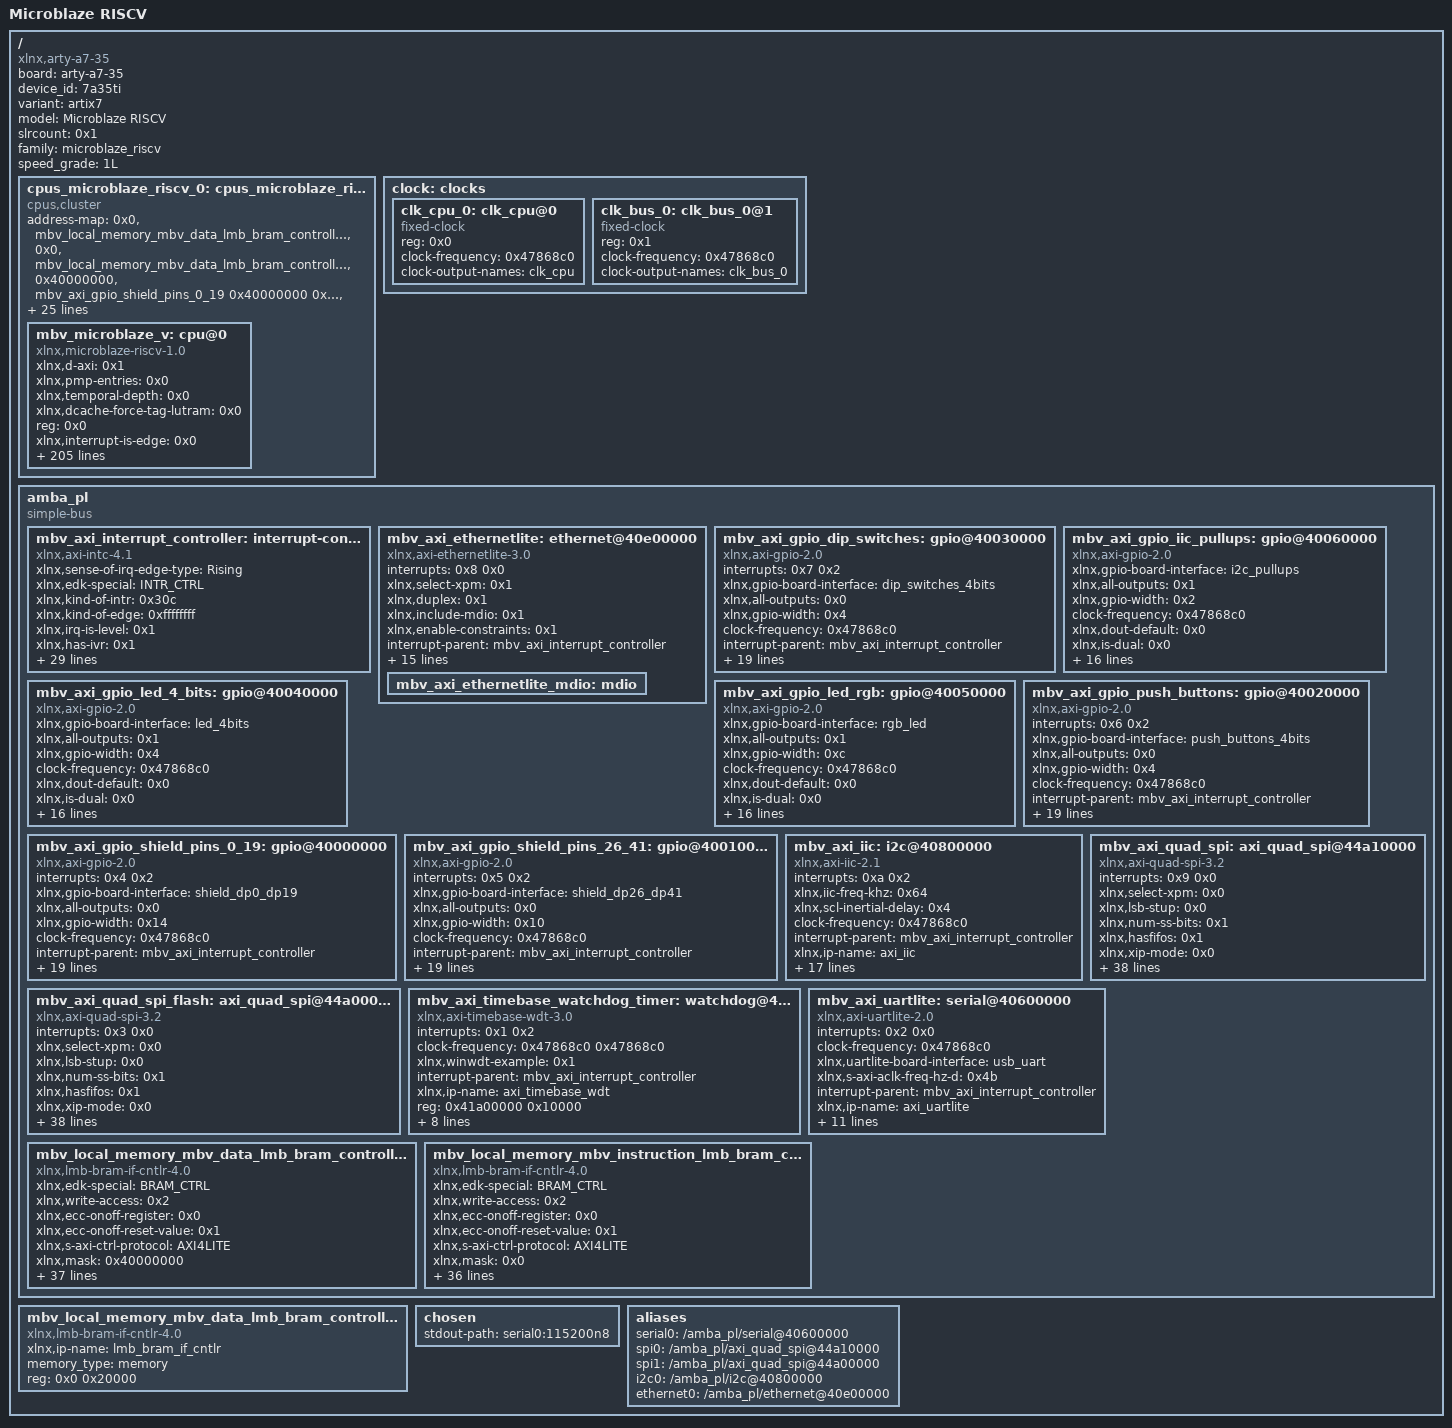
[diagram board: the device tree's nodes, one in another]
/dts-v1/;
/ {
        board = "arty-a7-35";
        compatible = "xlnx,arty-a7-35";
        device_id = "7a35ti";
        #address-cells = <0x1>;
        variant = "artix7";
        model = "Microblaze RISCV";
        #size-cells = <0x1>;
        slrcount = <0x1>;
        family = "microblaze_riscv";
        speed_grade = "1L";

        cpus_microblaze_riscv_0: cpus_microblaze_riscv@0 {
                phandle = <0x13>;
                #cpu-mask-cells = <0x1>;
                compatible = "cpus,cluster";
                #address-cells = <0x1>;
                #size-cells = <0x0>;
                address-map = <0x0 &mbv_local_memory_mbv_data_lmb_bram_controller_memory 0x0 0x20000>,
                 <0x0 &mbv_local_memory_mbv_data_lmb_bram_controller 0x0 0x20000>,
                 <0x40000000 &mbv_axi_gpio_shield_pins_0_19 0x40000000 0x10000>,
                 <0x40010000 &mbv_axi_gpio_shield_pins_26_41 0x40010000 0x10000>,
                 <0x40020000 &mbv_axi_gpio_push_buttons 0x40020000 0x10000>,
                 <0x40030000 &mbv_axi_gpio_dip_switches 0x40030000 0x10000>,
                 <0x40040000 &mbv_axi_gpio_led_4_bits 0x40040000 0x10000>,
                 <0x40050000 &mbv_axi_gpio_led_rgb 0x40050000 0x10000>,
                 <0x40060000 &mbv_axi_gpio_iic_pullups 0x40060000 0x10000>,
                 <0x40600000 &mbv_axi_uartlite 0x40600000 0x10000>,
                 <0x40800000 &mbv_axi_iic 0x40800000 0x10000>,
                 <0x40e00000 &mbv_axi_ethernetlite 0x40e00000 0x10000>,
                 <0x41200000 &mbv_axi_interrupt_controller 0x41200000 0x10000>,
                 <0x41a00000 &mbv_axi_timebase_watchdog_timer 0x41a00000 0x10000>,
                 <0x44a00000 &mbv_axi_quad_spi_flash 0x44a00000 0x10000>,
                 <0x44a10000 &mbv_axi_quad_spi 0x44a10000 0x10000>;
                #ranges-address-cells = <0x1>;
                #ranges-size-cells = <0x1>;

                mbv_microblaze_v: cpu@0 {
                        phandle = <0x14>;
                        xlnx,d-axi = <0x1>;
                        xlnx,pmp-entries = <0x0>;
                        xlnx,temporal-depth = <0x0>;
                        xlnx,dcache-force-tag-lutram = <0x0>;
                        reg = <0x0>;
                        xlnx,interrupt-is-edge = <0x0>;
                        xlnx,use-mmu = <0x3>;
                        xlnx,dc-axi-mon = <0x0>;
                        xlnx,debug-trace-async-reset = <0x0>;
                        xlnx,part = "xc7a35ticsg324-1l";
                        xlnx,use-config-reset = <0x0>;
                        xlnx,family = "artix7";
                        xlnx,use-sleep = <0x0>;
                        xlnx,d-lmb = <0x1>;
                        xlnx,enable-discrete-ports = <0x0>;
                        xlnx,debug-interface = <0x0>;
                        xlnx,use-ext-brk = <0x0>;
                        xlnx,debug-enabled = <0x1>;
                        xlnx,daddr-size = <0x20>;
                        xlnx,use-extended-fsl-instr = <0x0>;
                        xlnx,branch-target-cache-size = <0x0>;
                        bus-handle = <&amba_pl>;
                        xlnx,pmp-addr0 = <0x0>;
                        xlnx,pmp-addr1 = <0x0>;
                        xlnx,pmp-addr2 = <0x0>;
                        xlnx,pmp-addr3 = <0x0>;
                        xlnx,pmp-addr4 = <0x0>;
                        xlnx,edk-special = "microblaze_riscv";
                        xlnx,use-dcache = <0x0>;
                        xlnx,pmp-addr5 = <0x0>;
                        xlnx,use-muldiv = <0x2>;
                        xlnx,pmp-addr6 = <0x0>;
                        xlnx,use-axi-dp-ext-addr = <0x0>;
                        xlnx,pmp-addr7 = <0x0>;
                        xlnx,pmp-addr8 = <0x0>;
                        xlnx,pmp-addr9 = <0x0>;
                        xlnx,i-axi = <0x0>;
                        xlnx,icache-streams = <0x0>;
                        xlnx,i-lmb-has-prot = <0x0>;
                        xlnx,num-sync-ff-dbg-clk = <0x1>;
                        xlnx,icache-byte-size = <0x2000>;
                        xlnx,pmp-addr10 = <0x0>;
                        d-cache-size = <0x2000>;
                        xlnx,pmp-addr11 = <0x0>;
                        xlnx,pmp-addr12 = <0x0>;
                        xlnx,pmp-addr13 = <0x0>;
                        xlnx,pmp-addr14 = <0x0>;
                        xlnx,pmp-addr15 = <0x0>;
                        xlnx,avoid-primitives = <0x0>;
                        xlnx,pmp-addr16 = <0x0>;
                        xlnx,pmp-addr17 = <0x0>;
                        xlnx,pmp-addr18 = <0x0>;
                        xlnx,pdaddr-size = <0x22>;
                        xlnx,pmp-addr19 = <0x0>;
                        xlnx,pmp-addr20 = <0x0>;
                        xlnx,pmp-addr21 = <0x0>;
                        xlnx,i-lmb = <0x1>;
                        xlnx,pmp-addr22 = <0x0>;
                        xlnx,lmb-data-size = <0x20>;
                        xlnx,lockstep-select = <0x0>;
                        xlnx,pmp-addr23 = <0x0>;
                        timebase-frequency = <0x47868c0>;
                        xlnx,pmp-addr24 = <0x0>;
                        xlnx,dcache-data-width = <0x0>;
                        xlnx,icache-force-tag-lutram = <0x0>;
                        xlnx,pmp-addr25 = <0x0>;
                        xlnx,pmp-addr26 = <0x0>;
                        xlnx,use-branch-target-cache = <0x0>;
                        xlnx,pmp-addr27 = <0x0>;
                        xlnx,number-of-pc-brk = <0x8>;
                        xlnx,pmp-addr28 = <0x0>;
                        xlnx,imprecise-exceptions = <0x0>;
                        xlnx,pmp-addr29 = <0x0>;
                        xlnx,pmp-addr30 = <0x0>;
                        xlnx,pmp-addr31 = <0x0>;
                        xlnx,pmp-addr32 = <0x0>;
                        model = "microblaze_riscv,1.0";
                        xlnx,pmp-addr33 = <0x0>;
                        xlnx,pmp-addr34 = <0x0>;
                        xlnx,pmp-addr35 = <0x0>;
                        xlnx,pmp-addr36 = <0x0>;
                        d-cache-highaddr = <0x3fffffff>;
                        xlnx,optimization = <0x0>;
                        xlnx,pmp-addr37 = <0x0>;
                        xlnx,pmp-addr38 = <0x0>;
                        xlnx,pmp-addr39 = <0x0>;
                        xlnx,pmp-addr40 = <0x0>;
                        xlnx,pmp-addr41 = <0x0>;
                        xlnx,d-lmb-mon = <0x0>;
                        xlnx,pmp-addr42 = <0x0>;
                        xlnx,pmp-addr43 = <0x0>;
                        xlnx,pmp-addr44 = <0x0>;
                        xlnx,pmp-addr45 = <0x0>;
                        xlnx,pmp-addr46 = <0x0>;
                        xlnx,pmp-addr47 = <0x0>;
                        xlnx,pmp-addr48 = <0x0>;
                        xlnx,fault-tolerant = <0x0>;
                        xlnx,pmp-addr49 = <0x0>;
                        xlnx,pmp-addr50 = <0x0>;
                        xlnx,pmp-addr51 = <0x0>;
                        xlnx,pmp-enhancements = <0x0>;
                        d-cache-line-size = <0x10>;
                        xlnx,mmu-privileged-instr = <0x0>;
                        xlnx,pmp-addr52 = <0x0>;
                        clock-frequency = <0x47868c0>;
                        xlnx,pmp-addr53 = <0x0>;
                        xlnx,pmp-addr54 = <0x0>;
                        xlnx,pmp-addr55 = <0x0>;
                        xlnx,i-lmb-protocol = <0x0>;
                        xlnx,pmp-addr56 = <0x0>;
                        xlnx,pmp-addr57 = <0x0>;
                        xlnx,dp-axi-mon = <0x0>;
                        xlnx,pmp-addr58 = <0x0>;
                        xlnx,pmp-addr59 = <0x0>;
                        xlnx,pmp-addr60 = <0x0>;
                        xlnx,pmp-addr61 = <0x0>;
                        xlnx,pmp-addr62 = <0x0>;
                        xlnx,pmp-addr63 = <0x0>;
                        xlnx,debug-external-trace = <0x1>;
                        xlnx,addr-size = <0x20>;
                        xlnx,debug-num-progbuf = <0x2>;
                        xlnx,debug-event-counters = <0xd>;
                        xlnx,edk-iptype = "PROCESSOR";
                        xlnx,debug-latency-counters = <0x8>;
                        xlnx,interconnect = <0x2>;
                        xlnx,edge-is-positive = <0x1>;
                        xlnx,use-icache = <0x0>;
                        xlnx,async-wakeup = <0x3>;
                        xlnx,s-axi = <0x0>;
                        xlnx,use-ext-nm-brk = <0x0>;
                        xlnx,ic-axi-mon = <0x0>;
                        xlnx,archid = <0x1>;
                        xlnx,num-sync-ff-clk-irq = <0x1>;
                        xlnx,freq = <0x47868c0>;
                        xlnx,lockstep-master = <0x0>;
                        xlnx,pmp-cfg0 = <0x0>;
                        xlnx,pmp-cfg1 = <0x0>;
                        xlnx,iaddr-size = <0x20>;
                        xlnx,interrupt-mon = <0x0>;
                        xlnx,pmp-cfg2 = <0x0>;
                        xlnx,number-of-wr-addr-brk = <0x4>;
                        xlnx,pmp-cfg3 = <0x0>;
                        xlnx,pmp-cfg4 = <0x0>;
                        xlnx,use-interrupt = <0x2>;
                        xlnx,pmp-cfg5 = <0x0>;
                        xlnx,async-interrupt = <0x1>;
                        xlnx,pc-width = <0x11>;
                        xlnx,pmp-cfg6 = <0x0>;
                        xlnx,icache-victims = <0x0>;
                        xlnx,pmp-cfg7 = <0x0>;
                        xlnx,pmp-cfg8 = <0x0>;
                        xlnx,pmp-cfg9 = <0x0>;
                        xlnx,use-bitman-a = <0x1>;
                        xlnx,use-bitman-b = <0x1>;
                        xlnx,use-bitman-c = <0x1>;
                        xlnx,i-lmb-mon = <0x0>;
                        xlnx,dcache-byte-size = <0x2000>;
                        xlnx,data-size = <0x20>;
                        compatible = "xlnx,microblaze-riscv-1.0", "xlnx,microblaze_riscv";
                        xlnx,pmp-debug-inhibit = <0x0>;
                        xlnx,use-sstc = <0x1>;
                        xlnx,fsl-exception = <0x0>;
                        xlnx,dcache-use-writeback = <0x0>;
                        device_type = "cpu";
                        xlnx,impid = <0x1>;
                        xlnx,use-bitman-s = <0x1>;
                        xlnx,base-vectors = <0x0>;
                        xlnx,icache-line-len = <0x4>;
                        xlnx,d-lmb-has-prot = <0x0>;
                        xlnx,use-barrel = <0x1>;
                        xlnx,misaligned-exceptions = <0x1>;
                        xlnx,piaddr-size = <0x22>;
                        xlnx,use-bitman = <0xf>;
                        xlnx,dcache-line-len = <0x4>;
                        xlnx,num-sync-ff-clk = <0x2>;
                        xlnx,memory-ip-list = "mbv_local_memory_mbv_instruction_lmb_bram_controller_memory", "mbv_local_memory_mbv_data_lmb_bram_controller_memory";
                        xlnx,number-of-rd-addr-brk = <0x4>;
                        xlnx,use-counters = <0x1>;
                        xlnx,lockstep-slave = <0x0>;
                        interrupt-handle = <&mbv_axi_interrupt_controller>;
                        xlnx,pmp-cfg10 = <0x0>;
                        xlnx,pmp-cfg11 = <0x0>;
                        xlnx,debug-profile-size = <0x0>;
                        xlnx,pmp-cfg12 = <0x0>;
                        xlnx,pmp-cfg13 = <0x0>;
                        xlnx,pmp-cfg14 = <0x0>;
                        xlnx,pmp-cfg15 = <0x0>;
                        xlnx,debug-counter-width = <0x40>;
                        xlnx,icache-data-width = <0x0>;
                        xlnx,ip-name = "microblaze_riscv";
                        xlnx,ip-axi-mon = <0x0>;
                        xlnx,d-lmb-protocol = <0x0>;
                        xlnx,trace = <0x0>;
                        xlnx,ill-instr-exception = <0x2>;
                        xlnx,debug-trace-size = <0x0>;
                        xlnx,pmp-granularity = <0x2>;
                        xlnx,num-sync-ff-dbg-trace-clk = <0x2>;
                        xlnx,ecc-use-ce-exception = <0x0>;
                        xlnx,num-sync-ff-clk-debug = <0x2>;
                        xlnx,use-atomic = <0x1>;
                        xlnx,g-template-list = <0x0>;
                        xlnx,trap-enhancement = <0x0>;
                        xlnx,hartid = <0x0>;
                        xlnx,use-fpu = <0x0>;
                        xlnx,use-non-secure = <0x0>;
                        d-cache-baseaddr = <0x0>;
                        xlnx,use-compression = <0x1>;
                        xlnx,instr-size = <0x20>;
                        xlnx,fsl-links = <0x0>;
                        xlnx,dcache-victims = <0x0>;
                        xlnx,pmp-read-only = <0x0>;
                };
        };

        clock: clocks {
                phandle = <0x15>;
                #address-cells = <0x1>;
                #size-cells = <0x0>;

                clk_cpu_0: clk_cpu@0 {
                        phandle = <0x16>;
                        compatible = "fixed-clock";
                        reg = <0x0>;
                        clock-frequency = <0x47868c0>;
                        clock-output-names = "clk_cpu";
                        #clock-cells = <0x0>;
                };

                clk_bus_0: clk_bus_0@1 {
                        phandle = <0x12>;
                        compatible = "fixed-clock";
                        reg = <0x1>;
                        clock-frequency = <0x47868c0>;
                        clock-output-names = "clk_bus_0";
                        #clock-cells = <0x0>;
                };
        };

        amba_pl: amba_pl {
                phandle = <0x11>;
                ranges;
                compatible = "simple-bus";
                #address-cells = <0x1>;
                #size-cells = <0x1>;

                mbv_axi_interrupt_controller: interrupt-controller@41200000 {
                        phandle = <0xd>;
                        #interrupt-cells = <0x2>;
                        xlnx,sense-of-irq-edge-type = "Rising";
                        xlnx,edk-special = "INTR_CTRL";
                        xlnx,kind-of-intr = <0x30c>;
                        xlnx,kind-of-edge = <0xffffffff>;
                        xlnx,irq-is-level = <0x1>;
                        xlnx,has-ivr = <0x1>;
                        compatible = "xlnx,axi-intc-4.1", "xlnx,xps-intc-1.00.a";
                        xlnx,disable-synchronizers = <0x1>;
                        xlnx,kind-of-lvl = <0xffffffff>;
                        xlnx,ivar-reset-value = <0x10>;
                        xlnx,irq-active = <0x1>;
                        xlnx,en-cascade-mode = <0x0>;
                        xlnx,ip-name = "axi_intc";
                        xlnx,has-ilr = <0x0>;
                        reg = <0x41200000 0x10000>;
                        xlnx,addr-width = <0x20>;
                        xlnx,s-axi-aclk-freq-mhz = <0x4b>;
                        xlnx,num-sw-intr = <0x0>;
                        xlnx,irq-connection = <0x0>;
                        xlnx,num-intr-inputs = <0xb>;
                        xlnx,has-sie = <0x1>;
                        xlnx,enable-async = <0x0>;
                        xlnx,has-cie = <0x1>;
                        xlnx,num-sync-ff = <0x2>;
                        xlnx,edk-iptype = "PERIPHERAL";
                        xlnx,mb-clk-not-connected = <0x1>;
                        xlnx,has-ipr = <0x1>;
                        xlnx,sense-of-irq-level-type = "Active_High";
                        xlnx,cascade-master = <0x0>;
                        xlnx,processor-clk-freq-mhz = <0x4b>;
                        status = "okay";
                        xlnx,is-fast = <0x1>;
                        xlnx,has-fast = <0x1>;
                        xlnx,ivar-rst-val = <0x10>;
                        interrupt-controller;
                        xlnx,async-intr = <0xfffff900>;
                        xlnx,name = "mbv_axi_interrupt_controller";
                };

                mbv_axi_ethernetlite: ethernet@40e00000 {
                        phandle = <0xc>;
                        interrupts = <0x8 0x0>;
                        xlnx,select-xpm = <0x1>;
                        compatible = "xlnx,axi-ethernetlite-3.0", "xlnx,axi-ethernetlite-3.0", "xlnx,xps-ethernetlite-1.00.a";
                        xlnx,duplex = <0x1>;
                        xlnx,include-mdio = <0x1>;
                        xlnx,enable-constraints = <0x1>;
                        interrupt-parent = <&mbv_axi_interrupt_controller>;
                        xlnx,rx-ping-pong = <0x1>;
                        xlnx,ip-name = "axi_ethernetlite";
                        xlnx,tx-ping-pong = <0x1>;
                        reg = <0x40e00000 0x10000>;
                        xlnx,mii-board-interface = "eth_mii";
                        xlnx,mdio-board-interface = "eth_mdio_mdc";
                        xlnx,edk-iptype = "PERIPHERAL";
                        xlnx,include-global-buffers = <0x1>;
                        local-mac-address = [00 0A 23 00 00 00];
                        status = "okay";
                        xlnx,include-internal-loopback = <0x0>;
                        xlnx,use-board-flow;
                        xlnx,use-internal = <0x0>;
                        interrupt-names = "ip2intc_irpt";
                        xlnx,name = "mbv_axi_ethernetlite";
                        xlnx,axi-aclk-freq-mhz = <0x4b>;
                        xlnx,s-axi-id-width = <0x1>;

                        mbv_axi_ethernetlite_mdio: mdio {
                                phandle = <0x17>;
                                #address-cells = <0x1>;
                                #size-cells = <0x0>;
                        };
                };

                mbv_axi_gpio_dip_switches: gpio@40030000 {
                        phandle = <0x6>;
                        #interrupt-cells = <0x2>;
                        interrupts = <0x7 0x2>;
                        xlnx,gpio-board-interface = "dip_switches_4bits";
                        compatible = "xlnx,axi-gpio-2.0", "xlnx,xps-gpio-1.00.a";
                        xlnx,all-outputs = <0x0>;
                        #gpio-cells = <0x2>;
                        xlnx,gpio-width = <0x4>;
                        clock-frequency = <0x47868c0>;
                        interrupt-parent = <&mbv_axi_interrupt_controller>;
                        xlnx,dout-default = <0x0>;
                        xlnx,is-dual = <0x0>;
                        xlnx,ip-name = "axi_gpio";
                        xlnx,tri-default-2 = <0xffffffff>;
                        reg = <0x40030000 0x10000>;
                        xlnx,all-inputs-2 = <0x0>;
                        clocks = <&clk_bus_0>;
                        xlnx,all-outputs-2 = <0x0>;
                        gpio-controller;
                        xlnx,interrupt-present = <0x1>;
                        xlnx,gpio2-board-interface = "Custom";
                        xlnx,edk-iptype = "PERIPHERAL";
                        xlnx,dout-default-2 = <0x0>;
                        status = "okay";
                        xlnx,gpio2-width = <0x20>;
                        clock-names = "s_axi_aclk";
                        xlnx,use-board-flow;
                        interrupt-controller;
                        interrupt-names = "ip2intc_irpt";
                        xlnx,tri-default = <0xffffffff>;
                        xlnx,name = "mbv_axi_gpio_dip_switches";
                        xlnx,all-inputs = <0x1>;
                };

                mbv_axi_gpio_iic_pullups: gpio@40060000 {
                        phandle = <0x9>;
                        xlnx,gpio-board-interface = "i2c_pullups";
                        compatible = "xlnx,axi-gpio-2.0", "xlnx,xps-gpio-1.00.a";
                        xlnx,all-outputs = <0x1>;
                        #gpio-cells = <0x2>;
                        xlnx,gpio-width = <0x2>;
                        clock-frequency = <0x47868c0>;
                        xlnx,dout-default = <0x0>;
                        xlnx,is-dual = <0x0>;
                        xlnx,ip-name = "axi_gpio";
                        xlnx,tri-default-2 = <0xffffffff>;
                        reg = <0x40060000 0x10000>;
                        xlnx,all-inputs-2 = <0x0>;
                        clocks = <&clk_bus_0>;
                        xlnx,all-outputs-2 = <0x0>;
                        gpio-controller;
                        xlnx,interrupt-present = <0x0>;
                        xlnx,gpio2-board-interface = "Custom";
                        xlnx,edk-iptype = "PERIPHERAL";
                        xlnx,dout-default-2 = <0x0>;
                        status = "okay";
                        xlnx,gpio2-width = <0x20>;
                        clock-names = "s_axi_aclk";
                        xlnx,use-board-flow;
                        xlnx,tri-default = <0xffffffff>;
                        xlnx,name = "mbv_axi_gpio_iic_pullups";
                        xlnx,all-inputs = <0x0>;
                };

                mbv_axi_gpio_led_4_bits: gpio@40040000 {
                        phandle = <0x7>;
                        xlnx,gpio-board-interface = "led_4bits";
                        compatible = "xlnx,axi-gpio-2.0", "xlnx,xps-gpio-1.00.a";
                        xlnx,all-outputs = <0x1>;
                        #gpio-cells = <0x2>;
                        xlnx,gpio-width = <0x4>;
                        clock-frequency = <0x47868c0>;
                        xlnx,dout-default = <0x0>;
                        xlnx,is-dual = <0x0>;
                        xlnx,ip-name = "axi_gpio";
                        xlnx,tri-default-2 = <0xffffffff>;
                        reg = <0x40040000 0x10000>;
                        xlnx,all-inputs-2 = <0x0>;
                        clocks = <&clk_bus_0>;
                        xlnx,all-outputs-2 = <0x0>;
                        gpio-controller;
                        xlnx,interrupt-present = <0x0>;
                        xlnx,gpio2-board-interface = "Custom";
                        xlnx,edk-iptype = "PERIPHERAL";
                        xlnx,dout-default-2 = <0x0>;
                        status = "okay";
                        xlnx,gpio2-width = <0x20>;
                        clock-names = "s_axi_aclk";
                        xlnx,use-board-flow;
                        xlnx,tri-default = <0xffffffff>;
                        xlnx,name = "mbv_axi_gpio_led_4_bits";
                        xlnx,all-inputs = <0x0>;
                };

                mbv_axi_gpio_led_rgb: gpio@40050000 {
                        phandle = <0x8>;
                        xlnx,gpio-board-interface = "rgb_led";
                        compatible = "xlnx,axi-gpio-2.0", "xlnx,xps-gpio-1.00.a";
                        xlnx,all-outputs = <0x1>;
                        #gpio-cells = <0x2>;
                        xlnx,gpio-width = <0xc>;
                        clock-frequency = <0x47868c0>;
                        xlnx,dout-default = <0x0>;
                        xlnx,is-dual = <0x0>;
                        xlnx,ip-name = "axi_gpio";
                        xlnx,tri-default-2 = <0xffffffff>;
                        reg = <0x40050000 0x10000>;
                        xlnx,all-inputs-2 = <0x0>;
                        clocks = <&clk_bus_0>;
                        xlnx,all-outputs-2 = <0x0>;
                        gpio-controller;
                        xlnx,interrupt-present = <0x0>;
                        xlnx,gpio2-board-interface = "Custom";
                        xlnx,edk-iptype = "PERIPHERAL";
                        xlnx,dout-default-2 = <0x0>;
                        status = "okay";
                        xlnx,gpio2-width = <0x20>;
                        clock-names = "s_axi_aclk";
                        xlnx,use-board-flow;
                        xlnx,tri-default = <0xffffffff>;
                        xlnx,name = "mbv_axi_gpio_led_rgb";
                        xlnx,all-inputs = <0x0>;
                };

                mbv_axi_gpio_push_buttons: gpio@40020000 {
                        phandle = <0x5>;
                        #interrupt-cells = <0x2>;
                        interrupts = <0x6 0x2>;
                        xlnx,gpio-board-interface = "push_buttons_4bits";
                        compatible = "xlnx,axi-gpio-2.0", "xlnx,xps-gpio-1.00.a";
                        xlnx,all-outputs = <0x0>;
                        #gpio-cells = <0x2>;
                        xlnx,gpio-width = <0x4>;
                        clock-frequency = <0x47868c0>;
                        interrupt-parent = <&mbv_axi_interrupt_controller>;
                        xlnx,dout-default = <0x0>;
                        xlnx,is-dual = <0x0>;
                        xlnx,ip-name = "axi_gpio";
                        xlnx,tri-default-2 = <0xffffffff>;
                        reg = <0x40020000 0x10000>;
                        xlnx,all-inputs-2 = <0x0>;
                        clocks = <&clk_bus_0>;
                        xlnx,all-outputs-2 = <0x0>;
                        gpio-controller;
                        xlnx,interrupt-present = <0x1>;
                        xlnx,gpio2-board-interface = "Custom";
                        xlnx,edk-iptype = "PERIPHERAL";
                        xlnx,dout-default-2 = <0x0>;
                        status = "okay";
                        xlnx,gpio2-width = <0x20>;
                        clock-names = "s_axi_aclk";
                        xlnx,use-board-flow;
                        interrupt-controller;
                        interrupt-names = "ip2intc_irpt";
                        xlnx,tri-default = <0xffffffff>;
                        xlnx,name = "mbv_axi_gpio_push_buttons";
                        xlnx,all-inputs = <0x1>;
                };

                mbv_axi_gpio_shield_pins_0_19: gpio@40000000 {
                        phandle = <0x3>;
                        #interrupt-cells = <0x2>;
                        interrupts = <0x4 0x2>;
                        xlnx,gpio-board-interface = "shield_dp0_dp19";
                        compatible = "xlnx,axi-gpio-2.0", "xlnx,xps-gpio-1.00.a";
                        xlnx,all-outputs = <0x0>;
                        #gpio-cells = <0x2>;
                        xlnx,gpio-width = <0x14>;
                        clock-frequency = <0x47868c0>;
                        interrupt-parent = <&mbv_axi_interrupt_controller>;
                        xlnx,dout-default = <0x0>;
                        xlnx,is-dual = <0x0>;
                        xlnx,ip-name = "axi_gpio";
                        xlnx,tri-default-2 = <0xffffffff>;
                        reg = <0x40000000 0x10000>;
                        xlnx,all-inputs-2 = <0x0>;
                        clocks = <&clk_bus_0>;
                        xlnx,all-outputs-2 = <0x0>;
                        gpio-controller;
                        xlnx,interrupt-present = <0x1>;
                        xlnx,gpio2-board-interface = "Custom";
                        xlnx,edk-iptype = "PERIPHERAL";
                        xlnx,dout-default-2 = <0x0>;
                        status = "okay";
                        xlnx,gpio2-width = <0x20>;
                        clock-names = "s_axi_aclk";
                        xlnx,use-board-flow;
                        interrupt-controller;
                        interrupt-names = "ip2intc_irpt";
                        xlnx,tri-default = <0xffffffff>;
                        xlnx,name = "mbv_axi_gpio_shield_pins_0_19";
                        xlnx,all-inputs = <0x0>;
                };

                mbv_axi_gpio_shield_pins_26_41: gpio@40010000 {
                        phandle = <0x4>;
                        #interrupt-cells = <0x2>;
                        interrupts = <0x5 0x2>;
                        xlnx,gpio-board-interface = "shield_dp26_dp41";
                        compatible = "xlnx,axi-gpio-2.0", "xlnx,xps-gpio-1.00.a";
                        xlnx,all-outputs = <0x0>;
                        #gpio-cells = <0x2>;
                        xlnx,gpio-width = <0x10>;
                        clock-frequency = <0x47868c0>;
                        interrupt-parent = <&mbv_axi_interrupt_controller>;
                        xlnx,dout-default = <0x0>;
                        xlnx,is-dual = <0x0>;
                        xlnx,ip-name = "axi_gpio";
                        xlnx,tri-default-2 = <0xffffffff>;
                        reg = <0x40010000 0x10000>;
                        xlnx,all-inputs-2 = <0x0>;
                        clocks = <&clk_bus_0>;
                        xlnx,all-outputs-2 = <0x0>;
                        gpio-controller;
                        xlnx,interrupt-present = <0x1>;
                        xlnx,gpio2-board-interface = "Custom";
                        xlnx,edk-iptype = "PERIPHERAL";
                        xlnx,dout-default-2 = <0x0>;
                        status = "okay";
                        xlnx,gpio2-width = <0x20>;
                        clock-names = "s_axi_aclk";
                        xlnx,use-board-flow;
                        interrupt-controller;
                        interrupt-names = "ip2intc_irpt";
                        xlnx,tri-default = <0xffffffff>;
                        xlnx,name = "mbv_axi_gpio_shield_pins_26_41";
                        xlnx,all-inputs = <0x0>;
                };

                mbv_axi_iic: i2c@40800000 {
                        phandle = <0xb>;
                        interrupts = <0xa 0x2>;
                        xlnx,iic-freq-khz = <0x64>;
                        compatible = "xlnx,axi-iic-2.1", "xlnx,xps-iic-2.00.a";
                        xlnx,scl-inertial-delay = <0x4>;
                        clock-frequency = <0x47868c0>;
                        interrupt-parent = <&mbv_axi_interrupt_controller>;
                        xlnx,ip-name = "axi_iic";
                        xlnx,disable-setup-violation-check = <0x0>;
                        reg = <0x40800000 0x10000>;
                        clocks = <&clk_bus_0>;
                        xlnx,gpo-width = <0x1>;
                        xlnx,edk-iptype = "PERIPHERAL";
                        xlnx,static-timing-reg-width = <0x0>;
                        xlnx,sda-level = <0x1>;
                        status = "okay";
                        xlnx,use-board-flow;
                        xlnx,ten-bit-adr = <0x0>;
                        xlnx,default-value = <0x0>;
                        interrupt-names = "iic2intc_irpt";
                        xlnx,iic-board-interface = "i2c";
                        xlnx,timing-reg-width = <0x20>;
                        xlnx,iic-freq = <0x186a0>;
                        xlnx,smbus-pmbus-host = <0x0>;
                        xlnx,name = "mbv_axi_iic";
                        xlnx,axi-aclk-freq-mhz = <0x4b>;
                        xlnx,sda-inertial-delay = <0x4>;
                };

                mbv_axi_quad_spi: axi_quad_spi@44a10000 {
                        phandle = <0x10>;
                        interrupts = <0x9 0x0>;
                        xlnx,select-xpm = <0x0>;
                        compatible = "xlnx,axi-quad-spi-3.2", "xlnx,xps-spi-2.00.a";
                        xlnx,lsb-stup = <0x0>;
                        xlnx,num-ss-bits = <0x1>;
                        xlnx,hasfifos = <0x1>;
                        xlnx,xip-mode = <0x0>;
                        xlnx,use-startup-ext = <0x0>;
                        xlnx,s-axi4-addr-width = <0x18>;
                        xlnx,byte-level-interrupt-en = <0x0>;
                        num-cs = <0x1>;
                        xlnx,xip-perf-mode = <0x1>;
                        xlnx,sck-ratio = <0x10>;
                        xlnx,s-axi4-id-width = <0x1>;
                        fifo-size = <0x100>;
                        interrupt-parent = <&mbv_axi_interrupt_controller>;
                        xlnx,multiples16 = <0x1>;
                        xlnx,master-mode = <0x1>;
                        xlnx,shared-startup = <0x0>;
                        xlnx,ip-name = "axi_quad_spi";
                        xlnx,qspi-board-interface = "spi";
                        reg = <0x44a10000 0x10000>;
                        xlnx,dual-quad-mode = <0x0>;
                        xlnx,new-seq-en = <0x1>;
                        bits-per-word = <0x20>;
                        xlnx,num-transfer-bits = <0x20>;
                        xlnx,spi-memory = <0x3>;
                        xlnx,s-axi4-data-width = <0x20>;
                        xlnx,edk-iptype = "PERIPHERAL";
                        xlnx,slaveonly = <0x0>;
                        xlnx,use-startup-int = <0x0>;
                        xlnx,use-startup = <0x0>;
                        xlnx,type-of-axi4-interface = <0x1>;
                        xlnx,async-clk = <0x0>;
                        xlnx,spi-mode = <0x0>;
                        xlnx,sck-ratio1 = <0x1>;
                        status = "okay";
                        xlnx,fifo-depth = <0x100>;
                        xlnx,use-board-flow;
                        xlnx,uc-family = <0x0>;
                        xlnx,spi-mem-addr-bits = <0x18>;
                        xlnx,axi-interface = <0x1>;
                        interrupt-names = "ip2intc_irpt";
                        xlnx,Axi4-address = <0x44a10000>;
                        xlnx,fifo-included = <0x1>;
                        xlnx,sub-family = "artix7";
                        xlnx,name = "mbv_axi_quad_spi";
                };

                mbv_axi_quad_spi_flash: axi_quad_spi@44a00000 {
                        phandle = <0xf>;
                        interrupts = <0x3 0x0>;
                        xlnx,select-xpm = <0x0>;
                        compatible = "xlnx,axi-quad-spi-3.2", "xlnx,xps-spi-2.00.a";
                        xlnx,lsb-stup = <0x0>;
                        xlnx,num-ss-bits = <0x1>;
                        xlnx,hasfifos = <0x1>;
                        xlnx,xip-mode = <0x0>;
                        xlnx,use-startup-ext = <0x0>;
                        xlnx,s-axi4-addr-width = <0x18>;
                        xlnx,byte-level-interrupt-en = <0x0>;
                        num-cs = <0x1>;
                        xlnx,xip-perf-mode = <0x1>;
                        xlnx,sck-ratio = <0x2>;
                        xlnx,s-axi4-id-width = <0x1>;
                        fifo-size = <0x100>;
                        interrupt-parent = <&mbv_axi_interrupt_controller>;
                        xlnx,multiples16 = <0x1>;
                        xlnx,master-mode = <0x1>;
                        xlnx,shared-startup = <0x0>;
                        xlnx,ip-name = "axi_quad_spi";
                        xlnx,qspi-board-interface = "qspi_flash";
                        reg = <0x44a00000 0x10000>;
                        xlnx,dual-quad-mode = <0x0>;
                        xlnx,new-seq-en = <0x1>;
                        bits-per-word = <0x8>;
                        xlnx,num-transfer-bits = <0x8>;
                        xlnx,spi-memory = <0x3>;
                        xlnx,s-axi4-data-width = <0x20>;
                        xlnx,edk-iptype = "PERIPHERAL";
                        xlnx,slaveonly = <0x0>;
                        xlnx,use-startup-int = <0x0>;
                        xlnx,use-startup = <0x0>;
                        xlnx,type-of-axi4-interface = <0x1>;
                        xlnx,async-clk = <0x0>;
                        xlnx,spi-mode = <0x2>;
                        xlnx,sck-ratio1 = <0x1>;
                        status = "okay";
                        xlnx,fifo-depth = <0x100>;
                        xlnx,use-board-flow;
                        xlnx,uc-family = <0x0>;
                        xlnx,spi-mem-addr-bits = <0x18>;
                        xlnx,axi-interface = <0x1>;
                        interrupt-names = "ip2intc_irpt";
                        xlnx,Axi4-address = <0x44a00000>;
                        xlnx,fifo-included = <0x1>;
                        xlnx,sub-family = "artix7";
                        xlnx,name = "mbv_axi_quad_spi_flash";
                };

                mbv_axi_timebase_watchdog_timer: watchdog@41a00000 {
                        phandle = <0xe>;
                        compatible = "xlnx,axi-timebase-wdt-3.0", "xlnx,xps-timebase-wdt-1.00.a";
                        interrupts = <0x1 0x2>;
                        clock-frequency = <0x47868c0 0x47868c0>;
                        xlnx,winwdt-example = <0x1>;
                        interrupt-parent = <&mbv_axi_interrupt_controller>;
                        xlnx,ip-name = "axi_timebase_wdt";
                        reg = <0x41a00000 0x10000>;
                        clocks = <&clk_bus_0>;
                        xlnx,max-count-width = <0x20>;
                        xlnx,edk-iptype = "PERIPHERAL";
                        xlnx,sst-count-width = <0x8>;
                        xlnx,wdt-enable-once = <0x1>;
                        status = "okay";
                        interrupt-names = "wdt_interrupt";
                        xlnx,enable-window-wdt = <0x1>;
                        xlnx,name = "mbv_axi_timebase_watchdog_timer";
                        xlnx,wdt-interval = <0x1e>;
                };

                mbv_axi_uartlite: serial@40600000 {
                        phandle = <0xa>;
                        interrupts = <0x2 0x0>;
                        compatible = "xlnx,axi-uartlite-2.0", "xlnx,xps-uartlite-1.00.a";
                        clock-frequency = <0x47868c0>;
                        xlnx,uartlite-board-interface = "usb_uart";
                        xlnx,s-axi-aclk-freq-hz-d = <0x4b>;
                        interrupt-parent = <&mbv_axi_interrupt_controller>;
                        xlnx,ip-name = "axi_uartlite";
                        reg = <0x40600000 0x10000>;
                        xlnx,baudrate = <0x1c200>;
                        clocks = <&clk_bus_0>;
                        current-speed = <0x1c200>;
                        xlnx,use-parity = <0x0>;
                        xlnx,edk-iptype = "PERIPHERAL";
                        xlnx,odd-parity = <0x0>;
                        status = "okay";
                        xlnx,use-board-flow;
                        interrupt-names = "interrupt";
                        xlnx,name = "mbv_axi_uartlite";
                        xlnx,data-bits = <0x8>;
                        xlnx,parity = "No_Parity";
                };

                mbv_local_memory_mbv_data_lmb_bram_controller: lmb_bram_if_cntlr@0 {
                        phandle = <0x2>;
                        xlnx,edk-special = "BRAM_CTRL";
                        xlnx,write-access = <0x2>;
                        compatible = "xlnx,lmb-bram-if-cntlr-4.0", "xlnx,axi-bram-ctrl";
                        xlnx,ecc-onoff-register = <0x0>;
                        xlnx,ecc-onoff-reset-value = <0x1>;
                        xlnx,s-axi-ctrl-protocol = "AXI4LITE";
                        xlnx,mask = <0x40000000>;
                        xlnx,mask1 = <0x800000>;
                        xlnx,mask2 = <0x800000>;
                        xlnx,fault-inject = <0x0>;
                        xlnx,mask3 = <0x800000>;
                        xlnx,ip-name = "lmb_bram_if_cntlr";
                        xlnx,arbitration = <0x0>;
                        xlnx,num-lmb = <0x1>;
                        xlnx,mask4 = <0x800000>;
                        reg = <0x0 0x20000>;
                        xlnx,s-axi-ctrl-addr-width = <0x20>;
                        xlnx,mask5 = <0x800000>;
                        xlnx,ecc-status-registers = <0x0>;
                        xlnx,prot-cfg = <0xff>;
                        xlnx,mask6 = <0x800000>;
                        xlnx,lmb-protocol = <0x0>;
                        xlnx,ce-counter-width = <0x0>;
                        xlnx,prot-cfg1 = <0xff>;
                        xlnx,mask7 = <0x800000>;
                        xlnx,ecc = <0x0>;
                        xlnx,edk-iptype = "PERIPHERAL";
                        xlnx,prot-cfg2 = <0xff>;
                        xlnx,lmb-dwidth = <0x20>;
                        xlnx,interconnect = <0x0>;
                        xlnx,ce-failing-registers = <0x0>;
                        xlnx,prot-cfg3 = <0xff>;
                        xlnx,ue-failing-registers = <0x0>;
                        xlnx,prot-cfg4 = <0xff>;
                        xlnx,lmb-has-prot = <0x0>;
                        status = "okay";
                        xlnx,data-width = <0x20>;
                        xlnx,prot-cfg5 = <0xff>;
                        xlnx,s-axi-ctrl-data-width = <0x20>;
                        xlnx,prot-cfg6 = <0xff>;
                        xlnx,bram-awidth = <0x20>;
                        xlnx,prot-cfg7 = <0xff>;
                        xlnx,lmb-awidth = <0x22>;
                        xlnx,name = "mbv_local_memory_mbv_data_lmb_bram_controller";
                };

                mbv_local_memory_mbv_instruction_lmb_bram_controller: mbv_local_memory_mbv_instruction_lmb_bram_controller@0 {
                        phandle = <0x18>;
                        xlnx,edk-special = "BRAM_CTRL";
                        xlnx,write-access = <0x2>;
                        compatible = "xlnx,lmb-bram-if-cntlr-4.0", "xlnx,axi-bram-ctrl";
                        xlnx,ecc-onoff-register = <0x0>;
                        xlnx,ecc-onoff-reset-value = <0x1>;
                        xlnx,s-axi-ctrl-protocol = "AXI4LITE";
                        xlnx,mask = <0x0>;
                        xlnx,mask1 = <0x800000>;
                        xlnx,mask2 = <0x800000>;
                        xlnx,fault-inject = <0x0>;
                        xlnx,mask3 = <0x800000>;
                        xlnx,ip-name = "lmb_bram_if_cntlr";
                        xlnx,arbitration = <0x0>;
                        xlnx,num-lmb = <0x1>;
                        xlnx,mask4 = <0x800000>;
                        reg = <0x0 0x20000>;
                        xlnx,s-axi-ctrl-addr-width = <0x20>;
                        xlnx,mask5 = <0x800000>;
                        xlnx,ecc-status-registers = <0x0>;
                        xlnx,prot-cfg = <0xff>;
                        xlnx,mask6 = <0x800000>;
                        xlnx,lmb-protocol = <0x0>;
                        xlnx,ce-counter-width = <0x0>;
                        xlnx,prot-cfg1 = <0xff>;
                        xlnx,mask7 = <0x800000>;
                        xlnx,ecc = <0x0>;
                        xlnx,edk-iptype = "PERIPHERAL";
                        xlnx,prot-cfg2 = <0xff>;
                        xlnx,lmb-dwidth = <0x20>;
                        xlnx,interconnect = <0x0>;
                        xlnx,ce-failing-registers = <0x0>;
                        xlnx,prot-cfg3 = <0xff>;
                        xlnx,ue-failing-registers = <0x0>;
                        xlnx,prot-cfg4 = <0xff>;
                        xlnx,lmb-has-prot = <0x0>;
                        status = "okay";
                        xlnx,prot-cfg5 = <0xff>;
                        xlnx,s-axi-ctrl-data-width = <0x20>;
                        xlnx,prot-cfg6 = <0xff>;
                        xlnx,bram-awidth = <0x20>;
                        xlnx,prot-cfg7 = <0xff>;
                        xlnx,lmb-awidth = <0x22>;
                        xlnx,name = "mbv_local_memory_mbv_instruction_lmb_bram_controller";
                };
        };

        mbv_local_memory_mbv_data_lmb_bram_controller_memory: memory@0 {
                phandle = <0x1>;
                compatible = "xlnx,lmb-bram-if-cntlr-4.0";
                xlnx,ip-name = "lmb_bram_if_cntlr";
                device_type = "memory";
                memory_type = "memory";
                reg = <0x0 0x20000>;
        };

        chosen {
                stdout-path = "serial0:115200n8";
        };

        aliases {
                serial0 = "/amba_pl/serial@40600000";
                spi0 = "/amba_pl/axi_quad_spi@44a10000";
                spi1 = "/amba_pl/axi_quad_spi@44a00000";
                i2c0 = "/amba_pl/i2c@40800000";
                ethernet0 = "/amba_pl/ethernet@40e00000";
        };

        __symbols__ {
                cpus_microblaze_riscv_0 = "/cpus_microblaze_riscv@0";
                mbv_microblaze_v = "/cpus_microblaze_riscv@0/cpu@0";
                clock = "/clocks";
                clk_cpu_0 = "/clocks/clk_cpu@0";
                clk_bus_0 = "/clocks/clk_bus_0@1";
                amba_pl = "/amba_pl";
                mbv_axi_interrupt_controller = "/amba_pl/interrupt-controller@41200000";
                mbv_axi_ethernetlite = "/amba_pl/ethernet@40e00000";
                mbv_axi_ethernetlite_mdio = "/amba_pl/ethernet@40e00000/mdio";
                mbv_axi_gpio_dip_switches = "/amba_pl/gpio@40030000";
                mbv_axi_gpio_iic_pullups = "/amba_pl/gpio@40060000";
                mbv_axi_gpio_led_4_bits = "/amba_pl/gpio@40040000";
                mbv_axi_gpio_led_rgb = "/amba_pl/gpio@40050000";
                mbv_axi_gpio_push_buttons = "/amba_pl/gpio@40020000";
                mbv_axi_gpio_shield_pins_0_19 = "/amba_pl/gpio@40000000";
                mbv_axi_gpio_shield_pins_26_41 = "/amba_pl/gpio@40010000";
                mbv_axi_iic = "/amba_pl/i2c@40800000";
                mbv_axi_quad_spi = "/amba_pl/axi_quad_spi@44a10000";
                mbv_axi_quad_spi_flash = "/amba_pl/axi_quad_spi@44a00000";
                mbv_axi_timebase_watchdog_timer = "/amba_pl/watchdog@41a00000";
                mbv_axi_uartlite = "/amba_pl/serial@40600000";
                mbv_local_memory_mbv_data_lmb_bram_controller = "/amba_pl/lmb_bram_if_cntlr@0";
                mbv_local_memory_mbv_instruction_lmb_bram_controller = "/amba_pl/mbv_local_memory_mbv_instruction_lmb_bram_controller@0";
                mbv_local_memory_mbv_data_lmb_bram_controller_memory = "/memory@0";
        };
};
